# PY32T020xx register map
Vendor: Puya; Series: PY32L0; File version: 1.0.0
CPU: CM0+ r0p1, little endian, no MPU, no FPU, 4 interrupt priority bits
Registers are 32-bit, read-write, reset 0x0 unless marked. A register's access mark holds for its fields unless they carry their own. Offsets are from the block's base; [hi:lo] are bit positions; {n}, {i} and the like mark numbered series.

## SYSCFG — System configuration controller
Base 0x40010000
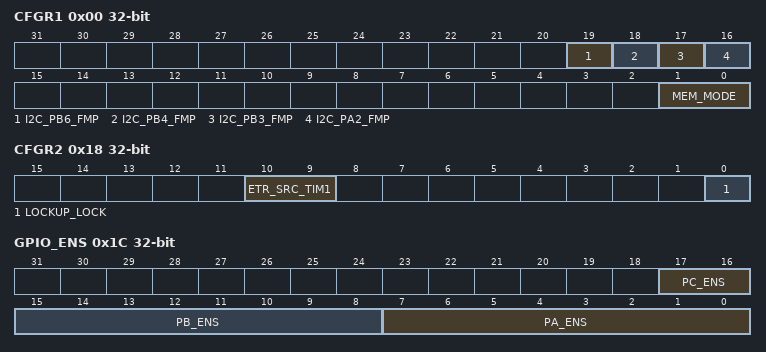
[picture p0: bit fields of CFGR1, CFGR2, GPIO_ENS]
0x00 CFGR1 — SYSCFG configuration register 1
  [19] I2C_PB6_FMP
  [18] I2C_PB4_FMP
  [17] I2C_PB3_FMP
  [16] I2C_PA2_FMP
  [1:0] MEM_MODE — Memory mapping selection bits
0x18 CFGR2 — SYSCFG configuration register 2
  [10:9] ETR_SRC_TIM1 — TIM1 ETR source selection
  [0] LOCKUP_LOCK — Cortex-M0+ LOCKUP bit enable bit
0x1C GPIO_ENS
  [17:16] PC_ENS, [15:8] PB_ENS, [7:0] PA_ENS

## TIM1 — Advanced timer
Base 0x40012C00
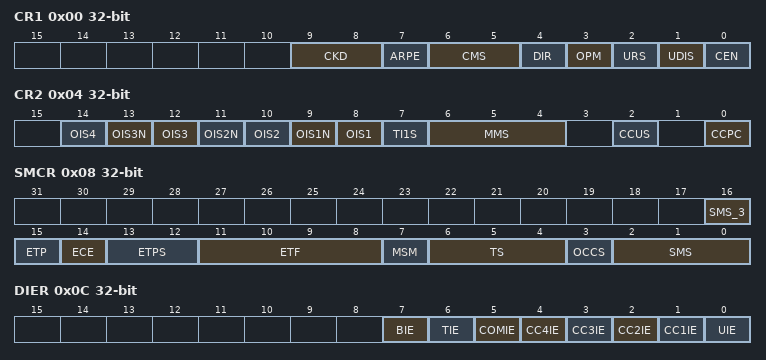
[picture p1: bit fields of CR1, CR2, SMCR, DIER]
0x00 CR1
  [9:8] CKD, [7] ARPE, [6:5] CMS, [4] DIR, [3] OPM, [2] URS, [1] UDIS, [0] CEN
0x04 CR2 (reset mask 0xF8)
  [2n+6] OIS{n} (n=1..4), [13] OIS3N, [11] OIS2N, [9] OIS1N, [7] TI1S, [6:4] MMS, [2] CCUS, [0] CCPC
0x08 SMCR (reset mask 0xFFF7)
  [16] SMS_3, [15] ETP, [14] ECE, [13:12] ETPS, [11:8] ETF, [7] MSM, [6:4] TS, [3] OCCS, [2:0] SMS
0x0C DIER (reset mask 0x5F5F)
  [7] BIE, [6] TIE, [5] COMIE, [n] CC{n}IE (n=1..4), [0] UIE
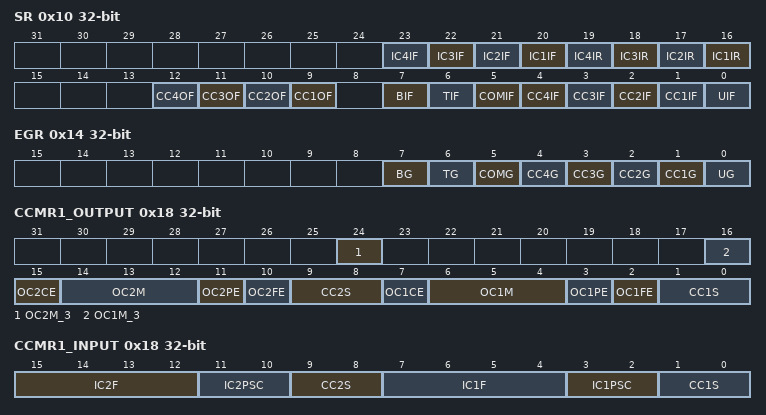
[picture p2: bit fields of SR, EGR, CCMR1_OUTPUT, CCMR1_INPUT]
0x10 SR (reset mask 0x1E5F)
  [n+19] IC{n}IF (n=1..4), [n+15] IC{n}IR (n=1..4), [n+8] CC{n}OF (n=1..4), [7] BIF, [6] TIF, [5] COMIF, [n] CC{n}IF (n=1..4), [0] UIF
0x14 EGR wo (reset mask 0x5F)
  [7] BG
  [6] TG
  [5] COMG
  [4] CC4G
  [3] CC3G
  [2] CC2G
  [1] CC1G — Capture/Compare 1 Generation
  [0] UG
0x18 CCMR1_OUTPUT (reset mask 0xFFFF)
  [24] OC2M_3, [16] OC1M_3, [15] OC2CE, [14:12] OC2M, [11] OC2PE, [10] OC2FE, [9:8] CC2S, [7] OC1CE, [6:4] OC1M, [3] OC1PE, [2] OC1FE, [1:0] CC1S
0x18 CCMR1_INPUT (alternate view of CCMR1_OUTPUT)
  [15:12] IC2F, [11:10] IC2PSC, [9:8] CC2S, [7:4] IC1F, [3:2] IC1PSC, [1:0] CC1S
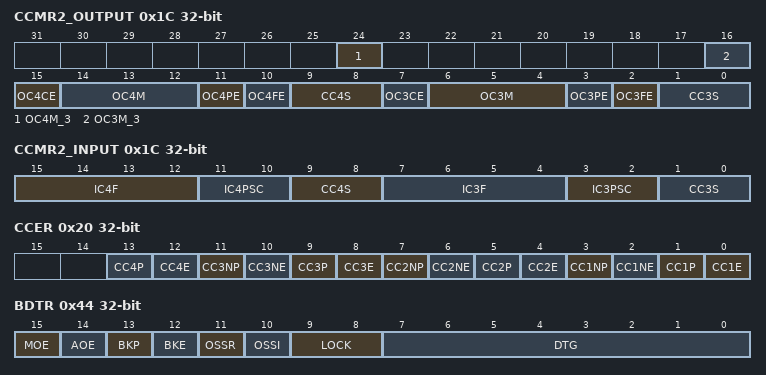
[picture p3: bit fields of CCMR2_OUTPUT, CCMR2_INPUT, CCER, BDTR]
0x1C CCMR2_OUTPUT (reset mask 0xFFFF)
  [24] OC4M_3, [16] OC3M_3, [15] OC4CE, [14:12] OC4M, [11] OC4PE, [10] OC4FE, [9:8] CC4S, [7] OC3CE, [6:4] OC3M, [3] OC3PE, [2] OC3FE, [1:0] CC3S
0x1C CCMR2_INPUT (alternate view of CCMR2_OUTPUT)
  [15:12] IC4F, [11:10] IC4PSC, [9:8] CC4S, [7:4] IC3F, [3:2] IC3PSC, [1:0] CC3S
0x20 CCER (reset mask 0x3333)
  [4n-3] CC{n}P (n=1..4), [4n-4] CC{n}E (n=1..4), [11] CC3NP, [10] CC3NE, [7] CC2NP, [6] CC2NE, [3] CC1NP, [2] CC1NE
0x24 CNT
  [15:0] CNT
0x28 PSC
  [15:0] PSC
0x2C ARR reset 0xFFFF
  [15:0] ARR
0x30 RCR reset 0xFFFF
  [7:0] REP
{0x30+4i} CCR{i} (i=1..4)
  [15:0] CCR{i}
0x44 BDTR
  [15] MOE, [14] AOE, [13] BKP, [12] BKE, [11] OSSR, [10] OSSI, [9:8] LOCK, [7:0] DTG

## TIM14 — General purpose timer
Base 0x40002000
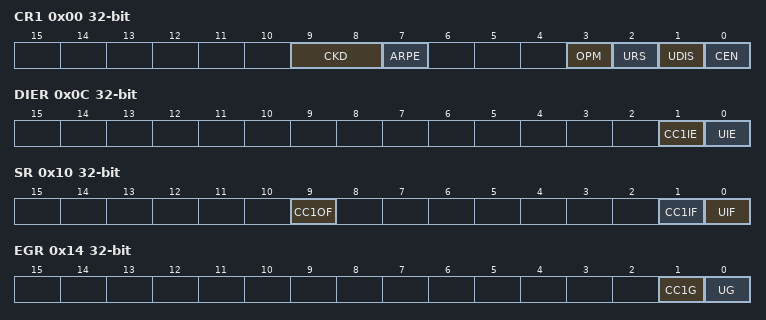
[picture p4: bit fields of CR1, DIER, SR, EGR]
0x00 CR1
  [9:8] CKD, [7] ARPE, [3] OPM, [2] URS, [1] UDIS, [0] CEN
0x0C DIER
  [1] CC1IE, [0] UIE
0x10 SR
  [9] CC1OF, [1] CC1IF, [0] UIF
0x14 EGR wo
  [1] CC1G — Capture/Compare 1 Generation
  [0] UG
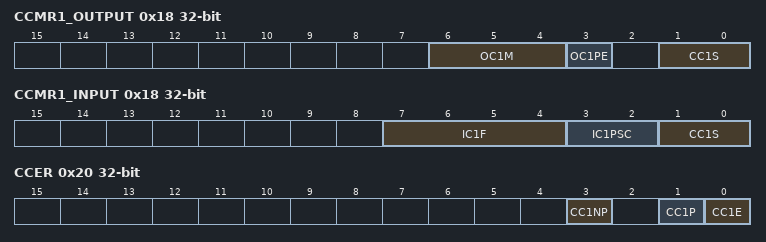
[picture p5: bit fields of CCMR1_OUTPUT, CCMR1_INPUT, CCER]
0x18 CCMR1_OUTPUT
  [6:4] OC1M, [3] OC1PE, [1:0] CC1S
0x18 CCMR1_INPUT (alternate view of CCMR1_OUTPUT)
  [7:4] IC1F, [3:2] IC1PSC, [1:0] CC1S
0x20 CCER (reset mask 0x3333)
  [3] CC1NP, [1] CC1P, [0] CC1E
0x24 CNT
  [15:0] CNT
0x28 PSC
  [15:0] PSC
0x2C ARR reset 0xFFFF
  [15:0] ARR
0x34 CCR1
  [15:0] CCR1
0x50 OR
  [1:0] TI1_RMP

## TK — Touch key
Base 0x40003800
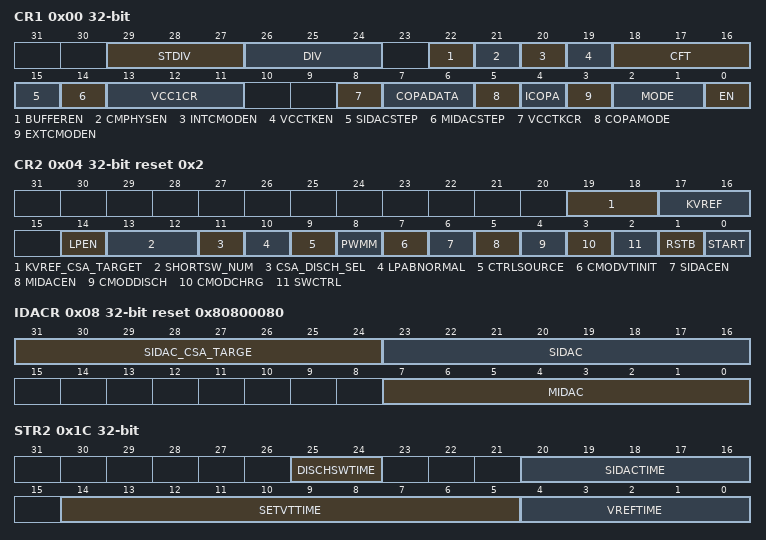
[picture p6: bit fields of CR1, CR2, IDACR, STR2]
0x00 CR1 — Control register 1
  [29:27] STDIV, [26:24] DIV, [22] BUFFEREN, [21] CMPHYSEN, [20] INTCMODEN, [19] VCCTKEN, [18:16] CFT, [15] SIDACSTEP, [14] MIDACSTEP, [13:11] VCC1CR, [8] VCCTKCR, [7:6] COPADATA, [5] COPAMODE, [4] ICOPA, [3] EXTCMODEN, [2:1] MODE, [0] EN
0x04 CR2 reset 0x2 — Control register 2
  [19:18] KVREF_CSA_TARGET, [17:16] KVREF, [14] LPEN, [13:12] SHORTSW_NUM, [11] CSA_DISCH_SEL, [10] LPABNORMAL, [9] CTRLSOURCE, [8] PWMM, [7] CMODVTINIT, [6] SIDACEN, [5] MIDACEN, [4] CMODDISCH, [3] CMODCHRG, [2] SWCTRL, [1] RSTB, [0] START
0x08 IDACR reset 0x80800080 — IDAC Control register
  [31:24] SIDAC_CSA_TARGE, [23:16] SIDAC, [7:0] MIDAC
0x0C KR — Key enable register
  [25:0] KEN
0x10 CSR — Channel Select register
  [25:0] CHS
0x14 UCR — Unsel Control register
  [25:0] COPAMODEIO
0x18 STR1 — Stable Time register 1
  [9:0] SETTIME
0x1C STR2 — Stable Time register 2
  [25:24] DISCHSWTIME, [20:16] SIDACTIME, [14:5] SETVTTIME, [4:0] VREFTIME
0x20 WR reset 0xFFFF — Window register
  [15:0] WIN
0x24 SDR — Switch Divide register
  [8:0] SWDIV
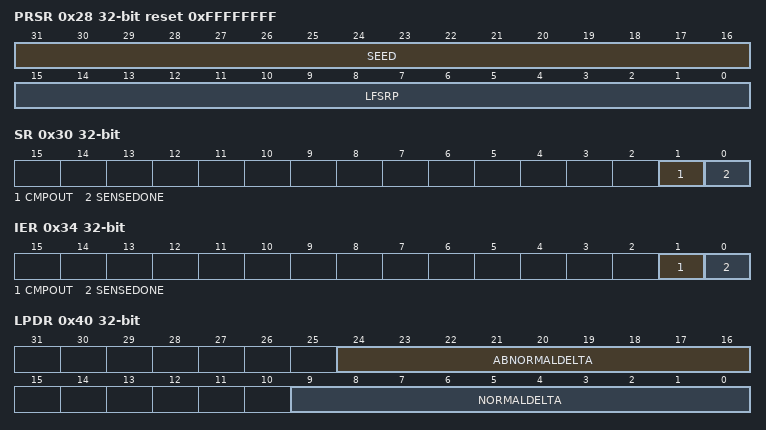
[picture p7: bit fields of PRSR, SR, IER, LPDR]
0x28 PRSR reset 0xFFFFFFFF — Pseudo Random Sequence register
  [31:16] SEED, [15:0] LFSRP
0x2C DR reset 0xFFFFFFFF — Data register
  [15:0] DATA
0x30 SR — Status register
  [1] CMPOUT, [0] SENSEDONE
0x34 IER — Interrupt enable register
  [1] CMPOUT, [0] SENSEDONE
0x38 ICR — Interrupt clear register
  [0] INTCLR
0x3C CDR — Compare Data register
  [15:0] CDATA
0x40 LPDR — Lowpower Delta register
  [24:16] ABNORMALDELTA, [9:0] NORMALDELTA
0x44 LPTR — Lowpower Time register
  [5:0] LPWAIT

## UART1 — Universal asynchronous receiver transmitter
Base 0x40004400
Same registers: UART3 0x40013800, UART2 0x40014400
0x00 DR — Data register
  [8:0] DR — Data value
0x04 BRR — Baud rate register
  [15:0] BRR
0x08 IIDR
  [2:0] IID
0x0C BUSY
  [0] BUSY
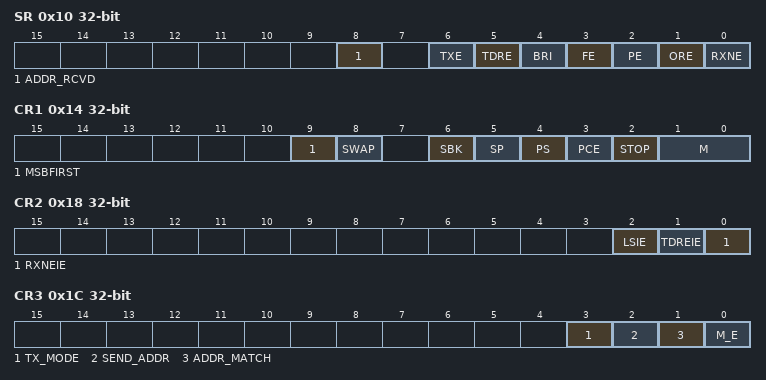
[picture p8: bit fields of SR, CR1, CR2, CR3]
0x10 SR — Status register
  [8] ADDR_RCVD ro
  [6] TXE ro
  [5] TDRE ro
  [4] BRI ro
  [3] FE ro — Framing error
  [2] PE — Parity error
  [1] ORE ro — Overrun error
  [0] RXNE ro
0x14 CR1 — Control register 1
  [9] MSBFIRST
  [8] SWAP
  [6] SBK
  [5] SP
  [4] PS — Parity selection
  [3] PCE — Parity control enable
  [2] STOP — STOP bits
  [1:0] M — Word length
0x18 CR2 — Control register 2
  [2] LSIE, [1] TDREIE, [0] RXNEIE
0x1C CR3 — Control register 3
  [3] TX_MODE, [2] SEND_ADDR, [1] ADDR_MATCH, [0] M_E
0x20 RAR
  [7:0] RAR
0x24 TAR
  [7:0] TAR
